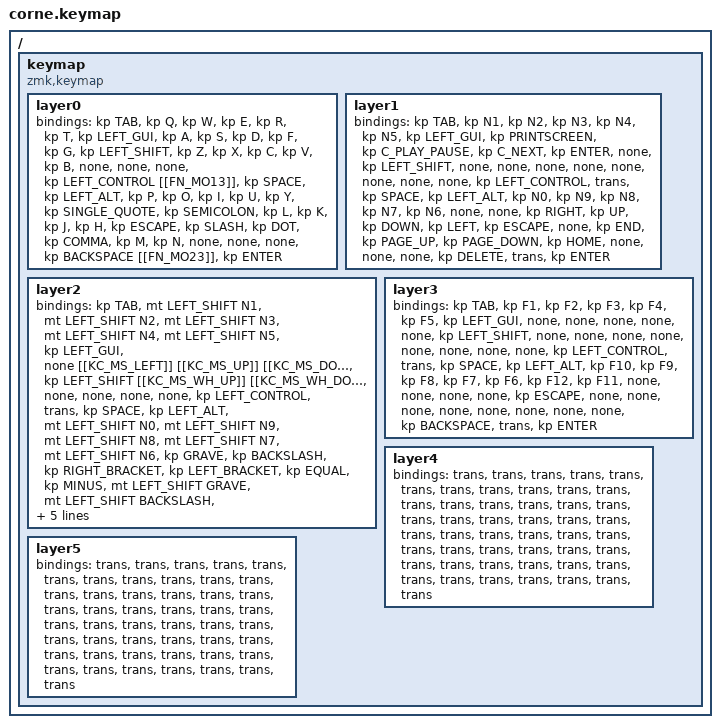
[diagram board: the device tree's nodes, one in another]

  /*
  * Copyright (c) 2020 The ZMK Contributors
  *
  * SPDX-License-Identifier: MIT
  */

  #include <behaviors.dtsi>
  #include <dt-bindings/zmk/keys.h>
  #include <dt-bindings/zmk/bt.h>
  #include <dt-bindings/zmk/ext_power.h>

  / {
    keymap {
      compatible = "zmk,keymap";
  layer0 {
          bindings = <
          &kp TAB &kp Q &kp W &kp E &kp R &kp T &kp LEFT_GUI &kp A &kp S &kp D &kp F &kp G &kp LEFT_SHIFT &kp Z &kp X &kp C &kp V &kp B &none &none &none &kp LEFT_CONTROL [[FN_MO13]] &kp SPACE &kp LEFT_ALT &kp P &kp O &kp I &kp U &kp Y &kp SINGLE_QUOTE &kp SEMICOLON &kp L &kp K &kp J &kp H &kp ESCAPE &kp SLASH &kp DOT &kp COMMA &kp M &kp N &none &none &none &kp BACKSPACE [[FN_MO23]] &kp ENTER
          >;
        };layer1 {
          bindings = <
          &kp TAB &kp N1 &kp N2 &kp N3 &kp N4 &kp N5 &kp LEFT_GUI &kp PRINTSCREEN &kp C_PLAY_PAUSE &kp C_NEXT &kp ENTER &none &kp LEFT_SHIFT &none &none &none &none &none &none &none &none &kp LEFT_CONTROL &trans &kp SPACE &kp LEFT_ALT &kp N0 &kp N9 &kp N8 &kp N7 &kp N6 &none &none &kp RIGHT &kp UP &kp DOWN &kp LEFT &kp ESCAPE &none &kp END &kp PAGE_UP &kp PAGE_DOWN &kp HOME &none &none &none &kp DELETE &trans &kp ENTER
          >;
        };layer2 {
          bindings = <
          &kp TAB &mt LEFT_SHIFT N1 &mt LEFT_SHIFT N2 &mt LEFT_SHIFT N3 &mt LEFT_SHIFT N4 &mt LEFT_SHIFT N5 &kp LEFT_GUI &none [[KC_MS_LEFT]] [[KC_MS_UP]] [[KC_MS_DOWN]] [[KC_MS_RIGHT]] &kp LEFT_SHIFT [[KC_MS_WH_UP]] [[KC_MS_WH_DOWN]] [[KC_MS_BTN2]] [[KC_MS_BTN1]] &none &none &none &none &kp LEFT_CONTROL &trans &kp SPACE &kp LEFT_ALT &mt LEFT_SHIFT N0 &mt LEFT_SHIFT N9 &mt LEFT_SHIFT N8 &mt LEFT_SHIFT N7 &mt LEFT_SHIFT N6 &kp GRAVE &kp BACKSLASH &kp RIGHT_BRACKET &kp LEFT_BRACKET &kp EQUAL &kp MINUS &mt LEFT_SHIFT GRAVE &mt LEFT_SHIFT BACKSLASH &mt LEFT_SHIFT RIGHT_BRACKET &mt LEFT_SHIFT LEFT_BRACKET &mt LEFT_SHIFT EQUAL &mt LEFT_SHIFT MINUS &none &none &none &kp BACKSPACE &trans &kp ENTER
          >;
        };layer3 {
          bindings = <
          &kp TAB &kp F1 &kp F2 &kp F3 &kp F4 &kp F5 &kp LEFT_GUI &none &none &none &none &none &kp LEFT_SHIFT &none &none &none &none &none &none &none &none &kp LEFT_CONTROL &trans &kp SPACE &kp LEFT_ALT &kp F10 &kp F9 &kp F8 &kp F7 &kp F6 &kp F12 &kp F11 &none &none &none &none &kp ESCAPE &none &none &none &none &none &none &none &none &kp BACKSPACE &trans &kp ENTER
          >;
        };layer4 {
          bindings = <
          &trans &trans &trans &trans &trans &trans &trans &trans &trans &trans &trans &trans &trans &trans &trans &trans &trans &trans &trans &trans &trans &trans &trans &trans &trans &trans &trans &trans &trans &trans &trans &trans &trans &trans &trans &trans &trans &trans &trans &trans &trans &trans &trans &trans &trans &trans &trans &trans
          >;
        };layer5 {
          bindings = <
          &trans &trans &trans &trans &trans &trans &trans &trans &trans &trans &trans &trans &trans &trans &trans &trans &trans &trans &trans &trans &trans &trans &trans &trans &trans &trans &trans &trans &trans &trans &trans &trans &trans &trans &trans &trans &trans &trans &trans &trans &trans &trans &trans &trans &trans &trans &trans &trans
          >;
        };
    };
  };
  
